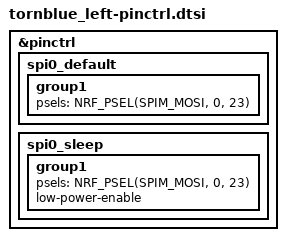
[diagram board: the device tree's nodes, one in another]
&pinctrl {
    spi0_default: spi0_default {
        group1 {
            psels = <NRF_PSEL(SPIM_MOSI, 0, 23)>;
        };
    };
    spi0_sleep: spi0_sleep {
        group1 {
            psels = <NRF_PSEL(SPIM_MOSI, 0, 23)>;
            low-power-enable;
        };
    };
};
